VERSION "AGL Virtual Car 1.0"

BS_:

BO_ 1001 Vehicle_Status_1: 8 VCAR_SIGNAL
  SG_ PT_VehicleSpeed : 7|15@0+ (0.015625,0) [0|511.984375] "km/h" VCAR_SIGNAL

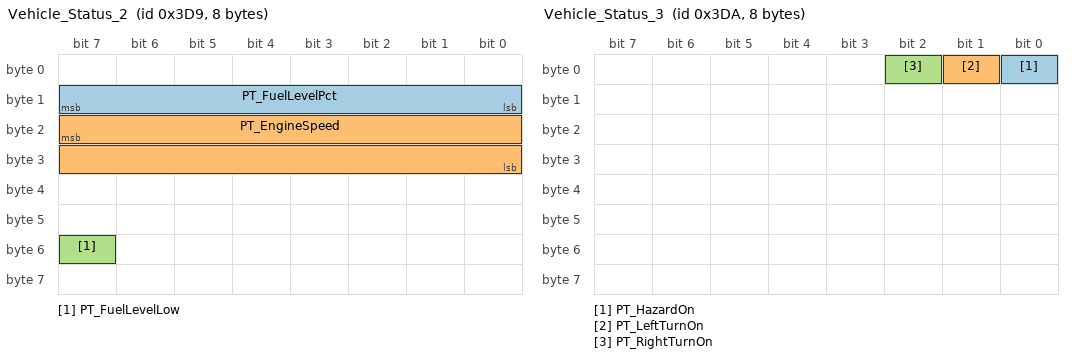
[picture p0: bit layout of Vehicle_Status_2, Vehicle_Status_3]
BO_ 985 Vehicle_Status_2: 8 VCAR_SIGNAL
  SG_ PT_FuelLevelPct : 8|8@1+ (0.392157,0) [0|100] "%" VCAR_SIGNAL
  SG_ PT_EngineSpeed : 23|16@0+ (0.25,0) [0|16383.75] "rpm" VCAR_SIGNAL
  SG_ PT_FuelLevelLow : 55|1@1+ (1,0) [0|1] "" VCAR_SIGNAL

BO_ 986 Vehicle_Status_3: 8 VCAR_SIGNAL
  SG_ PT_HazardOn : 0|1@1+ (1,0) [0|1] "" VCAR_SIGNAL
  SG_ PT_LeftTurnOn : 1|1@1+ (1,0) [0|1] "" VCAR_SIGNAL
  SG_ PT_RightTurnOn : 2|1@1+ (1,0) [0|1] "" VCAR_SIGNAL

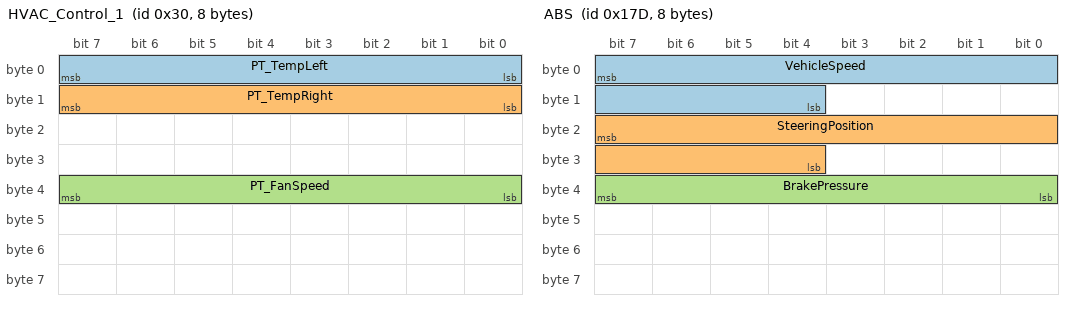
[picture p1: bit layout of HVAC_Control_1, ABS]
BO_ 48 HVAC_Control_1: 8 Vector_XXX
  SG_ PT_TempLeft : 7|8@0+ (0.4166666667,0) [0|100] "C" Vector_XXX
  SG_ PT_TempRight : 15|8@0+ (0.4166666667,0) [0|100] "C" Vector_XXX
  SG_ PT_FanSpeed : 39|8@0+ (0.392157,0) [0|100] "%" Vector_XXX

BO_ 401 Engine: 8 Vector__XXX
 SG_ ThrottlePosition : 63|8@0+ (0.392157,0) [0|100] "%" Vector__XXX

BO_ 381 ABS: 8 Vector__XXX
 SG_ VehicleSpeed : 7|12@0+ (0.0625,0) [0|255.9375] "km / h"  ECM_HS,BCM_HS
 SG_ SteeringPosition : 23|12@0+ (0.0439453125,-90) [-90|89.9560546875] "deg"  ECM_HS,BCM_HS
 SG_ BrakePressure : 39|8@0+ (75,0) [0|19125] "kPa"  ECM_HS,BCM_HS

BO_ 532 Transmission: 8 Vector__XXX
 SG_ Gear : 7|8@0+ (1,-1) [-1|127] ""  ECM_HS,BCM_HS

BO_ 533 Airbag: 8 Vector__XXX
 SG_ CollisionIntensity : 7|12@0+ (24.4140625,0) [0|100000] "N"  ECM_HS,BCM_HS

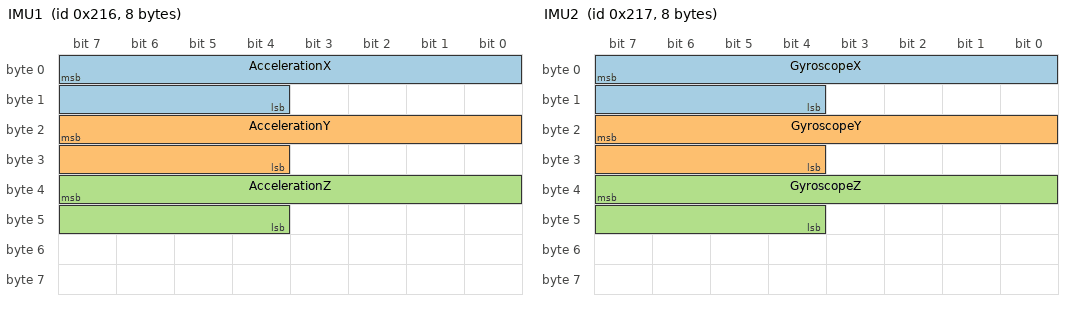
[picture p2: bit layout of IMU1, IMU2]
BO_ 534 IMU1: 8 Vector__XXX
 SG_ AccelerationX : 7|12@0+ (0.48828125,-1000) [-1000|1000] "m/s^2"  ECM_HS,BCM_HS
 SG_ AccelerationY : 23|12@0+ (0.48828125,-1000) [-1000|1000] "m/s^2"  ECM_HS,BCM_HS
 SG_ AccelerationZ : 39|12@0+ (0.48828125,-1000) [-1000|1000] "m/s^2"  ECM_HS,BCM_HS

BO_ 535 IMU2: 8 Vector__XXX
 SG_ GyroscopeX : 7|12@0+ (0.48828125,-1000) [-1000|1000] "rad/s"  ECM_HS,BCM_HS
 SG_ GyroscopeY : 23|12@0+ (0.48828125,-1000) [-1000|1000] "rad/s"  ECM_HS,BCM_HS
 SG_ GyroscopeZ : 39|12@0+ (0.48828125,-1000) [-1000|1000] "rad/s"  ECM_HS,BCM_HS

BO_ 536 GNSS: 8 Vector__XXX
 SG_ Latitude : 7|32@0+ (0.0000000419095158577,-90) [-90|90] "deg"  ECM_HS,BCM_HS
 SG_ Longitude : 39|32@0+ (0.00000008381903171539,-180) [-180|180] "deg"  ECM_HS,BCM_HS

BO_ 33 Steering_Wheel: 8 Vector_XXX
  SG_ SW_Previous : 39|1@1+ (1,0) [0|1] "" Vector_XXX
  SG_ SW_VolumeUp : 38|1@1+ (1,0) [0|1] "" Vector_XXX
  SG_ SW_Mode : 37|1@1+ (1,0) [0|1] "" Vector_XXX
  SG_ SW_VolumeDown : 36|1@1+ (1,0) [0|1] "" Vector_XXX
  SG_ SW_Next : 35|1@1+ (1,0) [0|1] "" Vector_XXX
  SG_ SW_Info : 33|1@1+ (1,0) [0|1] "" Vector_XXX
  SG_ SW_VolumeMute : 32|1@1+ (1,0) [0|1] "" Vector_XXX
  SG_ SW_Voice : 42|1@1+ (1,0) [0|1] "" Vector_XXX
  SG_ SW_PhoneHangup : 41|1@1+ (1,0) [0|1] "" Vector_XXX
  SG_ SW_PhoneCall : 40|1@1+ (1,0) [0|1] "" Vector_XXX
  SG_ SW_CruiseEnable : 55|1@1+ (1,0) [0|1] "" Vector_XXX
  SG_ SW_CruiseResume : 54|1@1+ (1,0) [0|1] "" Vector_XXX
  SG_ SW_CruiseSet : 52|1@1+ (1,0) [0|1] "" Vector_XXX
  SG_ SW_CruiseCancel : 51|1@1+ (1,0) [0|1] "" Vector_XXX
  SG_ SW_CruiseLimit : 49|1@1+ (1,0) [0|1] "" Vector_XXX
  SG_ SW_CruiseDistance : 48|1@1+ (1,0) [0|1] "" Vector_XXX
  SG_ SW_Horn : 63|1@1+ (1,0) [0|1] "" Vector_XXX
  SG_ SW_LaneDepartureWarning : 56|1@1+ (1,0) [0|1] "" Vector_XXX

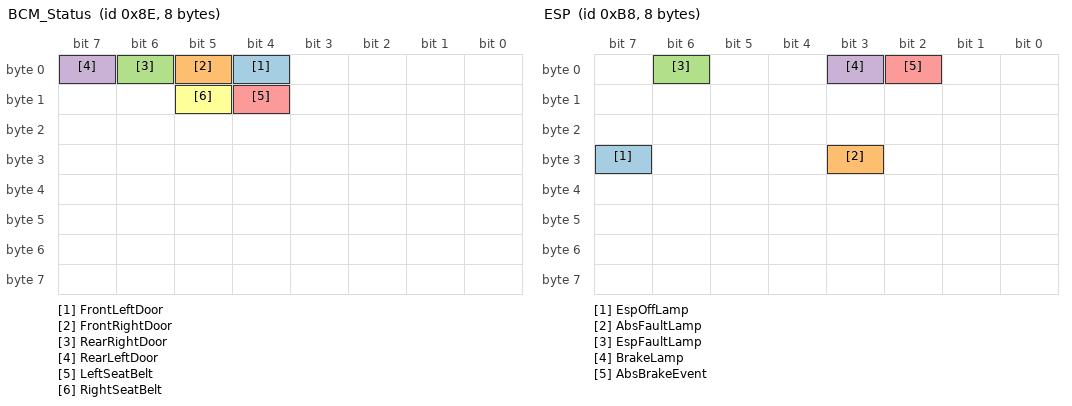
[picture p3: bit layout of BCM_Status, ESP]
BO_ 142 BCM_Status: 8 BCM
 SG_ FrontLeftDoor : 4|1@0+ (1,0) [0|1] ""  BCM
 SG_ FrontRightDoor : 5|1@0+ (1,0) [0|1] ""  BCM
 SG_ RearRightDoor : 6|1@0+ (1,0) [0|1] ""  BCM
 SG_ RearLeftDoor : 7|1@0+ (1,0) [0|1] ""  BCM
 SG_ LeftSeatBelt : 12|1@0+ (1,0) [0|1] ""  BCM
 SG_ RightSeatBelt : 13|1@0+ (1,0) [0|1] ""  BCM

BO_ 143 BCM_Status2: 8 BCM
 SG_ ImmobilizerFaultLamp : 4|1@0+ (1,0) [0|0] ""  BCM

BO_ 180 EV_Powertrain: 8 EVPWR
 SG_ EV_ShiftPosition : 12|3@0+ (1,0) [0|7] "" EVPWR
 SG_ EV_MotorFaultLamp : 1|1@0+ (1,0) [0|1] "" EVPWR

BO_ 184 ESP: 8 ESP
 SG_ EspOffLamp : 31|1@1+ (1,0) [0|1] ""  ESP
 SG_ AbsFaultLamp : 27|1@1+ (1,0) [0|1] ""  ESP
 SG_ EspFaultLamp : 6|1@1+ (1,0) [0|1] ""  ESP
 SG_ BrakeLamp : 3|1@1+ (1,0) [0|1] ""  ESP
 SG_ AbsBrakeEvent : 2|1@1+ (1,0) [0|1] ""  ESP

VAL_ 184 AbsBrakeEvent 1 "ACTIVE" 0 "NOT_ACTIVE" ;
VAL_ 184 BrakeLamp 1 "ACTIVE" 0 "NOT_ACTIVE" ;
VAL_ 184 EspFaultLamp 1 "Fault" 0 "Stable" ;
VAL_ 184 AbsFaultLamp 1 "Fault" 0 "Stable" ;
VAL_ 184 EspOffLamp 1 "Off" 0 "On" ;

BO_ 192 EPS_STATUS: 8 EPS
 SG_ EpsFaultLamp : 6|1@1+ (1,0) [0|1] ""  EPS
 SG_ EpsEnable : 0|1@1+ (1,0) [0|1] ""  EPS

VAL_ 192 EpsEnable 1 "Enable" 0 "Disable" ;
VAL_ 192 EpsFaultLamp 1 "Fault" 0 "Stable" ;
